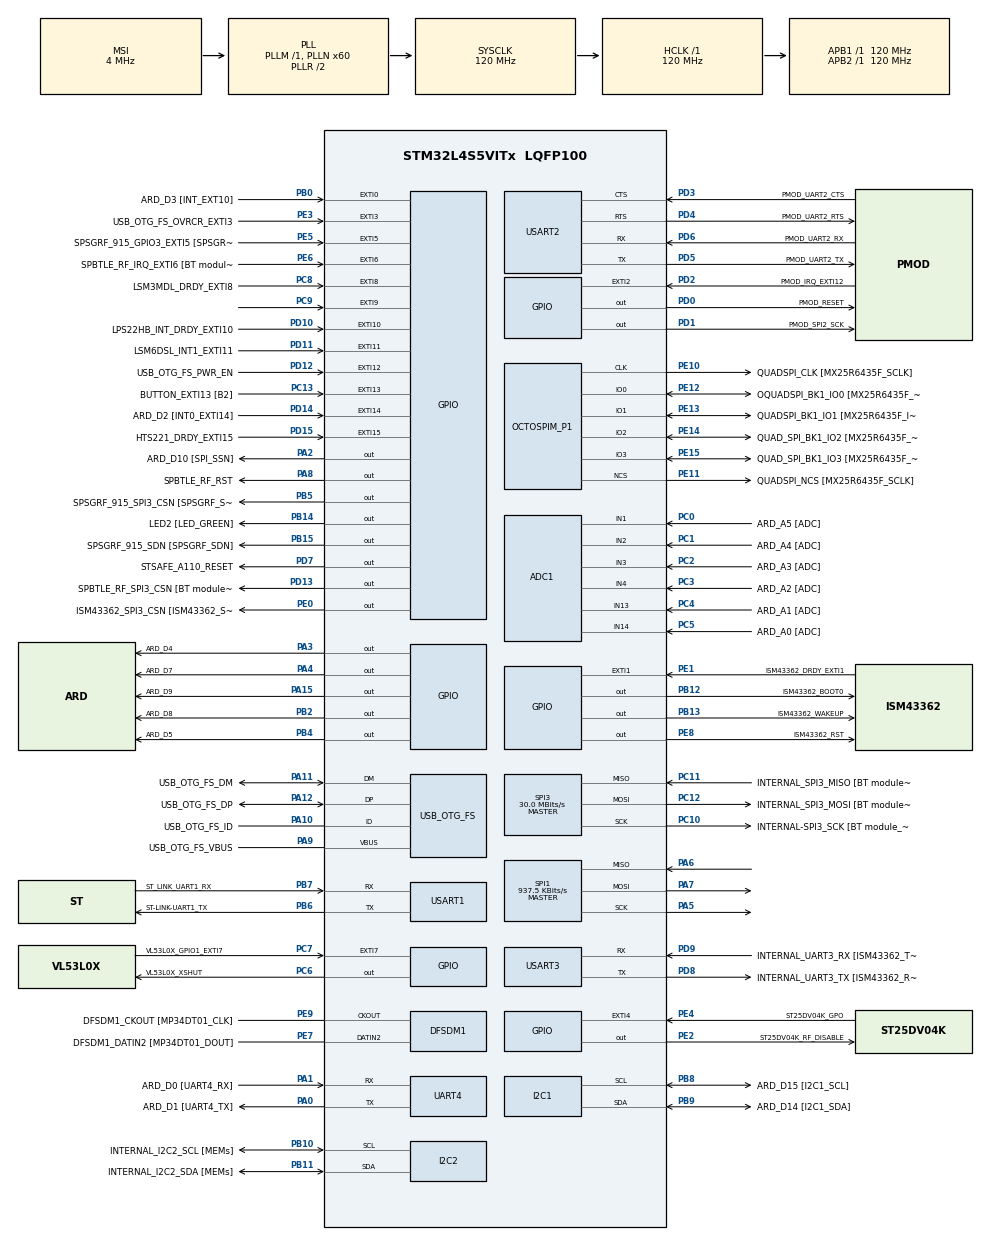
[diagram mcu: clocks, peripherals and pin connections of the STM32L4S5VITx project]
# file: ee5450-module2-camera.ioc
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PD12.GPIO_Label=USB_OTG_FS_PWR_EN
PC10.GPIO_PuPd=GPIO_NOPULL
PE10.GPIO_PuPd=GPIO_NOPULL
PD10.GPIO_PuPd=GPIO_NOPULL
PA15\ (JTDI).Signal=GPIO_Output
PC15-OSC32_OUT\ (PC15).Mode=LSE-External-Oscillator
PC14-OSC32_IN\ (PC14).Mode=LSE-External-Oscillator
PD8.GPIO_ModeDefaultPP=GPIO_MODE_AF_PP
PE13.GPIO_Mode=GPIO_MODE_AF_PP
NVIC.EXTI1_IRQn=true\:2\:0\:true\:false\:true\:true\:true
PD7.GPIO_PuPd=GPIO_NOPULL
SPI1.Direction=SPI_DIRECTION_2LINES
RCC.APB2TimFreq_Value=120000000
PC4.GPIO_Mode=GPIO_MODE_ANALOG_ADC_CONTROL
PB6.Signal=USART1_TX
PC7.Signal=GPXTI7
PB12.PinState=GPIO_PIN_RESET
SPI1.CalculateBaudRate=937.5 KBits/s
PD0.Signal=GPIO_Output
PD8.Signal=USART3_TX
PE1.Signal=GPXTI1
NVIC.EXTI15_10_IRQn=true\:2\:0\:true\:false\:true\:true\:true
PB7.GPIO_ModeDefaultPP=GPIO_MODE_AF_PP
PB12.GPIO_ModeDefaultOutputPP=GPIO_MODE_OUTPUT_PP
PC1.GPIO_PuPd=GPIO_NOPULL
PD1.GPIO_Label=PMOD_SPI2_SCK
PB12.GPIO_Label=ISM43362_BOOT0
PA13\ (JTMS/SWDIO).GPIO_Label=SYS_JTMS_SWDIO
PC4.GPIO_Label=ARD_A1 [ADC]
PB1.GPIO_Speed=GPIO_SPEED_FREQ_LOW
PE9.Signal=S_CKOUTDFSDM1
PB1.GPIO_Label=ARD_D6
SPI1.DataSize=SPI_DATASIZE_8BIT
PE4.GPIO_Label=ST25DV04K_GPO
PD14.GPIO_PuPd=GPIO_NOPULL
PA8.Signal=GPIO_Output
PE13.Mode=OCTOSPI1_IOL_Port1L
PB2.GPIO_PuPd=GPIO_NOPULL
PD11.GPIO_ModeDefaultEXTI=GPIO_MODE_IT_RISING
PA0.Signal=UART4_TX
PE9.GPIO_Mode=GPIO_MODE_AF_PP
Mcu.Package=LQFP100
PB9.Signal=I2C1_SDA
PB1.Signal=S_TIM3_CH4
PB14.GPIO_PuPd=GPIO_NOPULL
PD0.GPIO_ModeDefaultOutputPP=GPIO_MODE_OUTPUT_PP
SPI3.Mode=SPI_MODE_MASTER
PD12.Signal=GPXTI12
PB6.GPIO_FM6=__NULL
PA10.Signal=USB_OTG_FS_ID
PE12.GPIO_Label=OQUADSPI_BK1_IO0 [MX25R6435F_IO0]
PC11.Mode=Full_Duplex_Master
PE8.GPIO_Speed=GPIO_SPEED_FREQ_LOW
RCC.APB1TimFreq_Value=120000000
PD5.GPIO_Speed=GPIO_SPEED_FREQ_VERY_HIGH
PD3.GPIO_PuPd=GPIO_NOPULL
PE6.GPIO_PuPd=GPIO_NOPULL
PA4.GPIO_Label=ARD_D7
PA8.GPIO_Speed=GPIO_SPEED_FREQ_LOW
PD15.Signal=GPXTI15
RCC.HSI48_VALUE=48000000
PC6.GPIO_ModeDefaultOutputPP=GPIO_MODE_OUTPUT_PP
PA5.Mode=Full_Duplex_Master
PE12.Mode=OCTOSPI1_IOL_Port1L
ADC1.OffsetNumber-0\#ChannelRegularConversion=ADC_OFFSET_NONE
PC13.Signal=GPXTI13
PB6.GPIO_PuPd=GPIO_NOPULL
PD3.Signal=USART2_CTS
PC2.Signal=ADCx_IN3
PD15.GPIO_ModeDefaultEXTI=GPIO_MODE_IT_RISING
PD9.GPIO_ModeDefaultPP=GPIO_MODE_AF_PP
PD6.Mode=Asynchronous
PD10.Signal=GPXTI10
PC10.GPIO_Mode=GPIO_MODE_AF_PP
PB8.GPIO_Label=ARD_D15 [I2C1_SCL]
PE15.GPIO_Speed_High_Default=GPIO_SPEED_FREQ_VERY_HIGH
PB10.GPIO_Mode=GPIO_MODE_AF_OD
PA8.GPIO_Label=SPBTLE_RF_RST
PE8.GPIO_Label=ISM43362_RST
PB13.GPIO_Speed=GPIO_SPEED_FREQ_LOW
PD8.Mode=Asynchronous
PB14.Signal=GPIO_Output
PE2.GPIO_PuPd=GPIO_NOPULL
PA5.Signal=SPI1_SCK
PD7.PinState=GPIO_PIN_RESET
PC12.Mode=Full_Duplex_Master
PE1.GPIO_Label=ISM43362_DRDY_EXTI1
PB13.GPIO_PuPd=GPIO_NOPULL
PE14.Signal=OCTOSPIM_P1_IO2
PB15.GPIO_Label=SPSGRF_915_SDN [SPSGRF_SDN]
SPI1.Mode=SPI_MODE_MASTER
PD4.GPIO_Speed=GPIO_SPEED_FREQ_VERY_HIGH
PA0.GPIO_ModeDefaultPP=GPIO_MODE_AF_PP
PA1.GPIO_Label=ARD_D0 [UART4_RX]
PE3.GPIO_PuPd=GPIO_NOPULL
PA15\ (JTDI).GPIO_PuPd=GPIO_NOPULL
SH.ADCx_IN4.0=ADC1_IN4,IN4-Single-Ended
SPI1.NSSPMode=SPI_NSS_PULSE_DISABLE
PC7.GPIO_Label=VL53L0X_GPIO1_EXTI7
PC8.GPIO_PuPd=GPIO_NOPULL
ADC1.master=1
PE5.GPIO_Label=SPSGRF_915_GPIO3_EXTI5 [SPSGRF_GPIO_3]
PC12.GPIO_Label=INTERNAL_SPI3_MOSI [BT module_SPI_MOSI] [ISM43362_MOSI]
ProjectManager.HeapSize=0x200
PD0.GPIO_PuPd=GPIO_NOPULL
PD8.GPIO_Speed=GPIO_SPEED_FREQ_VERY_HIGH
NVIC.PriorityGroup=NVIC_PRIORITYGROUP_4
PE3.Signal=GPXTI3
PD2.Signal=GPXTI2
PB4\ (NJTRST).GPIO_PuPd=GPIO_NOPULL
Mcu.Family=STM32L4
PA6.Mode=Full_Duplex_Master
PH0-OSC_IN\ (PH0).Signal=RCC_OSC_IN
PE11.GPIO_Label=QUADSPI_NCS [MX25R6435F_SCLK]
PB2.GPIO_Speed=GPIO_SPEED_FREQ_LOW
PA0.GPIO_Label=ARD_D1 [UART4_TX]
PE2.GPIO_Speed=GPIO_SPEED_FREQ_LOW
PD9.GPIO_Speed=GPIO_SPEED_FREQ_VERY_HIGH
PD0.GPIO_Label=PMOD_RESET
PA11.Mode=OTG/Dual_Role_Device
PB4\ (NJTRST).GPIO_Speed=GPIO_SPEED_FREQ_LOW
PB13.GPIO_Label=ISM43362_WAKEUP
PD8.GPIO_PuPd=GPIO_NOPULL
PB15.Signal=GPIO_Output
PD9.Mode=Asynchronous
PD13.Signal=GPIO_Output
PC11.GPIO_PuPd=GPIO_NOPULL
PE11.GPIO_PuPd=GPIO_NOPULL
PA1.GPIO_ModeDefaultPP=GPIO_MODE_AF_PP
SH.ADCx_IN3.0=ADC1_IN3,IN3-Single-Ended
PD4.GPIO_Mode=GPIO_MODE_AF_PP
PD5.Mode=Asynchronous
PA9.GPIO_Mode=GPIO_MODE_INPUT
ADC1.Channel-0\#ChannelRegularConversion=ADC_CHANNEL_1
PH1-OSC_OUT\ (PH1).Mode=HSE-External-Oscillator
RCC.HSE_VALUE=8000000
PE2.GPIO_ModeDefaultOutputPP=GPIO_MODE_OUTPUT_PP
PE13.GPIO_PuPd=GPIO_NOPULL
PB0.GPIO_ModeDefaultEXTI=GPIO_MODE_IT_RISING
PD0.PinState=GPIO_PIN_RESET
PC11.GPIO_Label=INTERNAL_SPI3_MISO [BT module_SPI_MOSI] [ISM43362_MOSI]
PC13.GPIO_PuPd=GPIO_NOPULL
PB7.Signal=USART1_RX
PB7.GPIO_Label=ST_LINK_UART1_RX
PD13.GPIO_Label=SPBTLE_RF_SPI3_CSN [BT module_SPI_CS]
PA6.Signal=SPI1_MISO
PA15\ (JTDI).GPIO_ModeDefaultOutputPP=GPIO_MODE_OUTPUT_PP
PD5.GPIO_Label=PMOD_UART2_TX
SH.ADCx_IN1.0=ADC1_IN1,IN1-Single-Ended
PB5.GPIO_Label=SPSGRF_915_SPI3_CSN [SPSGRF_SPI_CS]
PE8.GPIO_ModeDefaultOutputPP=GPIO_MODE_OUTPUT_PP
PC5.Signal=ADCx_IN14
PD3.GPIO_Label=PMOD_UART2_CTS
PE14.GPIO_Mode=GPIO_MODE_AF_PP
PE7.Signal=S_DATAIN2DFSDM1
PD6.Signal=USART2_RX
PE2.GPIO_Label=ST25DV04K_RF_DISABLE
PB9.GPIO_FM9=__NULL
PA3.Signal=GPIO_Output
PE0.GPIO_PuPd=GPIO_NOPULL
PE3.GPIO_ModeDefaultEXTI=GPIO_MODE_IT_RISING
PB3\ (JTDO/TRACESWO).GPIO_Label=SYS_JTD0_SWO
RCC.MSI_VALUE=4000000
SH.ADCx_IN13.0=ADC1_IN13,IN13-Single-Ended
PE0.GPIO_ModeDefaultOutputPP=GPIO_MODE_OUTPUT_PP
PD15.GPIO_Label=HTS221_DRDY_EXTI15
PA10.Mode=OTG/Dual_Role_Device
PC11.Signal=SPI3_MISO
PC8.Signal=GPXTI8
PB4\ (NJTRST).PinState=GPIO_PIN_RESET
PC10.Mode=Full_Duplex_Master
PE4.GPIO_ModeDefaultEXTI=GPIO_MODE_IT_RISING
PE14.GPIO_Label=QUAD_SPI_BK1_IO2 [MX25R6435F_IO2]
PD9.Signal=USART3_RX
PA9.GPIO_PuPd=GPIO_NOPULL
PA12.GPIO_Label=USB_OTG_FS_DP
PH1-OSC_OUT\ (PH1).Signal=RCC_OSC_OUT
PD8.GPIO_Label=INTERNAL_UART3_TX [ISM43362_RX]
USART1.VirtualMode-Asynchronous=VM_ASYNC
PD4.GPIO_PuPd=GPIO_NOPULL
PA9.Mode=Activate_VBUS
PE0.PinState=GPIO_PIN_RESET
PB14.PinState=GPIO_PIN_RESET
PB10.GPIO_Label=INTERNAL_I2C2_SCL [MEMs]
PB9.Mode=I2C
RCC.USBFreq_Value=48000000
PD10.GPIO_Label=LPS22HB_INT_DRDY_EXTI10
PB14.GPIO_ModeDefaultOutputPP=GPIO_MODE_OUTPUT_PP
PA1.Signal=UART4_RX
PB6.GPIO_ModeDefaultPP=GPIO_MODE_AF_PP
PE10.GPIO_Speed_High_Default=GPIO_SPEED_FREQ_VERY_HIGH
PE10.GPIO_Mode=GPIO_MODE_AF_PP
board=B-L4S5I-IOT01A
PD13.GPIO_Speed=GPIO_SPEED_FREQ_LOW
RCC.VCOOutputFreq_Value=240000000
PA1.GPIO_Speed=GPIO_SPEED_FREQ_VERY_HIGH
RCC.ADCFreq_Value=48000000
PC1.GPIO_Label=ARD_A4 [ADC]
PE11.GPIO_Mode=GPIO_MODE_AF_PP
PD5.GPIO_PuPd=GPIO_NOPULL
PE14.GPIO_PuPd=GPIO_NOPULL
PA15\ (JTDI).GPIO_Label=ARD_D9
PE0.Signal=GPIO_Output
PE7.GPIO_Label=DFSDM1_DATIN2 [MP34DT01_DOUT]
PE12.Signal=OCTOSPIM_P1_IO0
PE12.GPIO_Mode=GPIO_MODE_AF_PP
RCC.SYSCLKFreq_VALUE=120000000
PC14-OSC32_IN\ (PC14).Signal=RCC_OSC32_IN
NVIC.EXTI9_5_IRQn=true\:2\:0\:true\:false\:true\:true\:true
PB2.GPIO_Label=ARD_D8
PE15.GPIO_PuPd=GPIO_NOPULL
PD3.GPIO_Mode=GPIO_MODE_AF_PP
RCC.HSI_VALUE=16000000
PA8.GPIO_PuPd=GPIO_NOPULL
PD14.GPIO_ModeDefaultEXTI=GPIO_MODE_IT_RISING
RCC.PLLN=60
PB8.GPIO_Speed=GPIO_SPEED_FREQ_VERY_HIGH
PC12.GPIO_Speed=GPIO_SPEED_FREQ_VERY_HIGH
PD6.GPIO_Speed=GPIO_SPEED_FREQ_VERY_HIGH
PD7.GPIO_ModeDefaultOutputPP=GPIO_MODE_OUTPUT_PP
PB12.Signal=GPIO_Output
PB0.GPIO_PuPd=GPIO_NOPULL
PA3.GPIO_Label=ARD_D4
PD6.GPIO_PuPd=GPIO_NOPULL
PB4\ (NJTRST).Signal=GPIO_Output
PD5.GPIO_ModeDefaultPP=GPIO_MODE_AF_PP
PE15.GPIO_Mode=GPIO_MODE_AF_PP
SPI3.Direction=SPI_DIRECTION_2LINES
SPI3.VirtualType=VM_MASTER
SPI1.VirtualType=VM_MASTER
PB10.Mode=I2C
PC12.Signal=SPI3_MOSI
PB14.GPIO_Label=LED2 [LED_GREEN]
PE8.GPIO_PuPd=GPIO_NOPULL
PB7.GPIO_FM7=__NULL
PC6.GPIO_Label=VL53L0X_XSHUT
PB6.GPIO_Label=ST-LINK-UART1_TX
PB13.Signal=GPIO_Output
PD3.GPIO_Speed=GPIO_SPEED_FREQ_VERY_HIGH
PD6.GPIO_Label=PMOD_UART2_RX
PE6.GPIO_Label=SPBTLE_RF_IRQ_EXTI6 [BT module_SPI_IRQ]
RCC.SYSCLKSource=RCC_SYSCLKSOURCE_PLLCLK
PB11.GPIO_Speed=GPIO_SPEED_FREQ_VERY_HIGH
USART3.VirtualMode-Asynchronous=VM_ASYNC
PA14\ (JTCK/SWCLK).Signal=SYS_JTCK-SWCLK
PD4.Signal=USART2_RTS
PB6.Mode=Asynchronous
PC3.Signal=ADCx_IN4
PE5.Signal=GPXTI5
PD10.GPIO_ModeDefaultEXTI=GPIO_MODE_IT_RISING
PA1.GPIO_PuPd=GPIO_NOPULL
PD2.GPIO_ModeDefaultEXTI=GPIO_MODE_IT_RISING
PB2.Signal=GPIO_Output
VP_OCTOSPI1_VS_quad.Mode=quad_mode
PE11.GPIO_Speed_High_Default=GPIO_SPEED_FREQ_VERY_HIGH
PA0.Mode=Asynchronous
PC11.GPIO_Speed=GPIO_SPEED_FREQ_VERY_HIGH
PE2.Signal=GPIO_Output
PA14\ (JTCK/SWCLK).Mode=Serial_Wire
PA8.GPIO_ModeDefaultOutputPP=GPIO_MODE_OUTPUT_PP
PD3.Mode=CTS_RTS
PE10.Signal=OCTOSPIM_P1_CLK
ADC1.SamplingTime-0\#ChannelRegularConversion=ADC_SAMPLETIME_2CYCLES_5
PA2.GPIO_ModeDefaultOutputPP=GPIO_MODE_OUTPUT_PP
SH.ADCx_IN14.0=ADC1_IN14,IN14-Single-Ended
PC6.GPIO_PuPd=GPIO_NOPULL
PB8.GPIO_PuPdOD=GPIO_PULLUP
PA14\ (JTCK/SWCLK).GPIO_Label=SYS_JTCK_SWCLK
PC2.GPIO_Mode=GPIO_MODE_ANALOG_ADC_CONTROL
PD4.Mode=CTS_RTS
PC12.GPIO_PuPd=GPIO_NOPULL
PB11.GPIO_Mode=GPIO_MODE_AF_OD
PE10.GPIO_Label=QUADSPI_CLK [MX25R6435F_SCLK]
PD9.GPIO_PuPd=GPIO_NOPULL
PB2.GPIO_ModeDefaultOutputPP=GPIO_MODE_OUTPUT_PP
PH0-OSC_IN\ (PH0).Mode=HSE-External-Oscillator
PC6.GPIO_Speed=GPIO_SPEED_FREQ_LOW
PE12.GPIO_PuPd=GPIO_NOPULL
PB7.GPIO_PuPd=GPIO_NOPULL
ADC1.Rank-0\#ChannelRegularConversion=1
PD9.GPIO_Label=INTERNAL_UART3_RX [ISM43362_TX]
PD2.GPIO_PuPd=GPIO_NOPULL
PA9.GPIO_Label=USB_OTG_FS_VBUS
PB10.GPIO_PuPdOD=GPIO_PULLUP
PB11.GPIO_PuPdOD=GPIO_PULLUP
PE10.Mode=O1_P1_CLK
PC6.Signal=GPIO_Output
PB11.GPIO_Label=INTERNAL_I2C2_SDA [MEMs]
PD7.Signal=GPIO_Output
PD1.Signal=GPIO_Output
PA11.GPIO_Label=USB_OTG_FS_DM
PE1.GPIO_PuPd=GPIO_NOPULL
PC0.Signal=ADCx_IN1
PD0.GPIO_Speed=GPIO_SPEED_FREQ_LOW
PA0.GPIO_Speed=GPIO_SPEED_FREQ_VERY_HIGH
PE0.GPIO_Speed=GPIO_SPEED_FREQ_LOW
PB11.Mode=I2C
PB14.GPIO_Speed=GPIO_SPEED_FREQ_LOW
PA9.Signal=USB_OTG_FS_VBUS
I2C1.Timing=0x307075B1
PC7.GPIO_PuPd=GPIO_NOPULL
PE9.GPIO_Label=DFSDM1_CKOUT [MP34DT01_CLK]
PB10.Signal=I2C2_SCL
PC6.PinState=GPIO_PIN_RESET
PE6.GPIO_ModeDefaultEXTI=GPIO_MODE_IT_RISING
PA15\ (JTDI).GPIO_Speed=GPIO_SPEED_FREQ_LOW
PD12.GPIO_ModeDefaultEXTI=GPIO_MODE_IT_RISING
PE7.GPIO_Speed=GPIO_SPEED_FREQ_LOW
PA1.Mode=Asynchronous
PB13.PinState=GPIO_PIN_RESET
PE15.Signal=OCTOSPIM_P1_IO3
PE8.Signal=GPIO_Output
PC11.GPIO_Mode=GPIO_MODE_AF_PP
PE4.GPIO_PuPd=GPIO_NOPULL
PA4.Signal=GPIO_Output
OCTOSPI1.MemoryType=HAL_OSPI_MEMTYPE_MACRONIX
PC12.GPIO_Mode=GPIO_MODE_AF_PP
PB5.Signal=GPIO_Output
PE13.GPIO_Label=QUADSPI_BK1_IO1 [MX25R6435F_IO1]
PD11.Signal=GPXTI11
PA11.Signal=USB_OTG_FS_DM
PC5.GPIO_Mode=GPIO_MODE_ANALOG_ADC_CONTROL
PE12.GPIO_Speed_High_Default=GPIO_SPEED_FREQ_VERY_HIGH
PC8.GPIO_ModeDefaultEXTI=GPIO_MODE_IT_RISING
PB8.Mode=I2C
PC3.GPIO_Label=ARD_A2 [ADC]
PA15\ (JTDI).PinState=GPIO_PIN_RESET
PB4\ (NJTRST).GPIO_Label=ARD_D5
PB6.GPIO_Speed=GPIO_SPEED_FREQ_VERY_HIGH
PB12.GPIO_PuPd=GPIO_NOPULL
PB0.Signal=GPXTI0
PC1.Signal=ADCx_IN2
PD2.GPIO_Label=PMOD_IRQ_EXTI12
PA13\ (JTMS/SWDIO).Signal=SYS_JTMS-SWDIO
PE15.Mode=OCTOSPI1_IOL_Port1L
PC3.GPIO_Mode=GPIO_MODE_ANALOG_ADC_CONTROL
PA2.GPIO_PuPd=GPIO_NOPULL
PE7.GPIO_PuPd=GPIO_NOPULL
PE8.PinState=GPIO_PIN_RESET
RCC.CortexFreq_Value=120000000
PB10.GPIO_Speed=GPIO_SPEED_FREQ_VERY_HIGH
SH.ADCx_IN2.0=ADC1_IN2,IN2-Single-Ended
PC10.Signal=SPI3_SCK
I2C2.Timing=0x307075B1
PA2.GPIO_Speed=GPIO_SPEED_FREQ_LOW
PC0.GPIO_Label=ARD_A5 [ADC]
PE9.GPIO_Speed=GPIO_SPEED_FREQ_LOW
PB0.GPIO_Label=ARD_D3 [INT_EXT10]
PC10.GPIO_Speed=GPIO_SPEED_FREQ_VERY_HIGH
PE14.GPIO_Speed_High_Default=GPIO_SPEED_FREQ_VERY_HIGH
PC13.GPIO_Label=BUTTON_EXTI13 [B2]
PB11.Signal=I2C2_SDA
ProjectManager.StackSize=0x400
PD11.GPIO_PuPd=GPIO_NOPULL
PA12.Signal=USB_OTG_FS_DP
PE11.Mode=OCTOSPI1_Port1_NCS
PD11.GPIO_Label=LSM6DSL_INT1_EXTI11
RCC.HCLKFreq_Value=120000000
PB13.GPIO_ModeDefaultOutputPP=GPIO_MODE_OUTPUT_PP
RCC.AHBFreq_Value=120000000
PC1.GPIO_Mode=GPIO_MODE_ANALOG_ADC_CONTROL
USART2.VirtualMode-Asynchronous=VM_ASYNC
PD7.GPIO_Speed=GPIO_SPEED_FREQ_LOW
PA2.PinState=GPIO_PIN_SET
PE13.Signal=OCTOSPIM_P1_IO1
PA10.GPIO_Label=USB_OTG_FS_ID
PE4.Signal=GPXTI4
PD7.GPIO_Label=STSAFE_A110_RESET
PC7.GPIO_ModeDefaultEXTI=GPIO_MODE_IT_RISING
PA0.GPIO_PuPd=GPIO_NOPULL
PA2.GPIO_Label=ARD_D10 [SPI_SSN]
PD15.GPIO_PuPd=GPIO_NOPULL
PE0.GPIO_Label=ISM43362_SPI3_CSN [ISM43362_SSN]
PB4\ (NJTRST).GPIO_ModeDefaultOutputPP=GPIO_MODE_OUTPUT_PP
PB9.GPIO_Speed=GPIO_SPEED_FREQ_VERY_HIGH
PE13.GPIO_Speed_High_Default=GPIO_SPEED_FREQ_VERY_HIGH
PC0.GPIO_PuPd=GPIO_NOPULL
SPI1.BaudRatePrescaler=SPI_BAUDRATEPRESCALER_128
PC2.GPIO_Label=ARD_A3 [ADC]
PA8.PinState=GPIO_PIN_RESET
RCC.PLLSAI1N=24
PB7.GPIO_Speed=GPIO_SPEED_FREQ_VERY_HIGH
PA7.Mode=Full_Duplex_Master
PA13\ (JTMS/SWDIO).Mode=Serial_Wire
PB9.GPIO_Label=ARD_D14 [I2C1_SDA]
PC10.GPIO_Label=INTERNAL-SPI3_SCK [BT module_SPI_MOSI] [ISM43362_MOSI]
PE2.PinState=GPIO_PIN_RESET
PC4.GPIO_PuPd=GPIO_NOPULL
PB8.GPIO_FM8=__NULL
PC4.Signal=ADCx_IN13
SH.S_DATAIN2DFSDM1.0=DFSDM1_DATIN2,PDM_SPI_input_from_ch2_and_internal_clock
PC15-OSC32_OUT\ (PC15).Signal=RCC_OSC32_OUT
PD5.Signal=USART2_TX
PE1.GPIO_ModeDefaultEXTI=GPIO_MODE_IT_RISING
VP_RNG_VS_RNG.Mode=RNG_Activate
PC5.GPIO_PuPd=GPIO_NOPULL
PD6.GPIO_ModeDefaultPP=GPIO_MODE_AF_PP
PC8.GPIO_Label=LSM3MDL_DRDY_EXTI8
PE15.GPIO_Label=QUAD_SPI_BK1_IO3 [MX25R6435F_IO3]
PB3\ (JTDO/TRACESWO).Signal=SYS_JTDO-SWO
ProjectManager.TargetToolchain=STM32CubeIDE
PE11.Signal=OCTOSPIM_P1_NCS
PB12.GPIO_Speed=GPIO_SPEED_FREQ_LOW
PE7.GPIO_Mode=GPIO_MODE_AF_PP
PB9.GPIO_Mode=GPIO_MODE_AF_OD
RCC.APB2Freq_Value=120000000
SPI3.CalculateBaudRate=30.0 MBits/s
PC0.GPIO_Mode=GPIO_MODE_ANALOG_ADC_CONTROL
PD4.GPIO_Label=PMOD_UART2_RTS
PE14.Mode=OCTOSPI1_IOL_Port1L
SH.S_CKOUTDFSDM1.0=DFSDM1_CKOUT,PDM_SPI_input_from_ch2_and_internal_clock
SPI3.BaudRatePrescaler=SPI_BAUDRATEPRESCALER_4
PD13.GPIO_PuPd=GPIO_NOPULL
PD14.GPIO_Label=ARD_D2 [INT0_EXTI14]
PC2.GPIO_PuPd=GPIO_NOPULL
PE6.Signal=GPXTI6
PB2.PinState=GPIO_PIN_RESET
Mcu.Name=STM32L4S5VITx
PA2.Signal=GPIO_Output
PD14.Signal=GPXTI14
PA12.Mode=OTG/Dual_Role_Device
PC13.GPIO_ModeDefaultEXTI=GPIO_MODE_IT_RISING_FALLING
PC5.GPIO_Label=ARD_A0 [ADC]
PD13.GPIO_ModeDefaultOutputPP=GPIO_MODE_OUTPUT_PP
PB7.Mode=Asynchronous
PB9.GPIO_PuPdOD=GPIO_PULLUP
ADC1.NbrOfConversionFlag=1
PB8.Signal=I2C1_SCL
PE3.GPIO_Label=USB_OTG_FS_OVRCR_EXTI3
PC9.Signal=GPXTI9
PD13.PinState=GPIO_PIN_RESET
PB8.GPIO_Mode=GPIO_MODE_AF_OD
RCC.APB1Freq_Value=120000000
PD12.GPIO_PuPd=GPIO_NOPULL
PC3.GPIO_PuPd=GPIO_NOPULL
SH.S_TIM3_CH4.0=TIM3_CH4
PA7.Signal=SPI1_MOSI
PE9.GPIO_PuPd=GPIO_NOPULL

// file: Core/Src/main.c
/* USER CODE BEGIN Header */
/**
  ******************************************************************************
  * @file           : main.c
  * @brief          : Main program body (only the threads are in this file)
  ******************************************************************************
  */
/* USER CODE END Header */
#include "main.h"
#include "adc.h"
#include "dfsdm.h"
#include "i2c.h"
#include "octospi.h"
#include "rng.h"
#include "spi.h"
#include "usart.h"
#include "usb_otg.h"
#include "gpio.h"

/* USER CODE BEGIN Includes */
#include <stdio.h>
#include "sensor_telemetry_setup.h"
#include "sensor_telemetry.h"
/* USER CODE END Includes */

/* USER CODE BEGIN PM */
/* USER CODE BEGIN PTD */
/* USER CODE END PM */

/* USER CODE BEGIN PV */
TX_EVENT_FLAGS_GROUP global_event_flags;
TX_BYTE_POOL global_byte_pool;
ULONG global_memory_area[(sizeof(struct global_data_t) / sizeof(ULONG)) + 10 * sizeof(ULONG)];
extern SPI_HandleTypeDef hspi_wifi;
/* USER CODE END PV */

void SystemClock_Config(void);
/* USER CODE BEGIN PFP */
void thread_camera_setup(ULONG global_data_ulong);
void thread_camera_stream(ULONG global_data_ulong);
void thread_network_setup(ULONG global_data_ulong);
_Noreturn void blink_PA_5(ULONG global_data_ulong);
_Noreturn void blink_PB_14(ULONG global_data_ulong);
_Noreturn void thread_temperature(ULONG global_data_ulong);
_Noreturn void thread_accelerometer(ULONG global_data_ulong);
/* USER CODE END PFP */

/* USER CODE BEGIN 0 */
/**
 * @brief interrupt handler to set software interrupts
 * @param GPIO_Pin
 */
void HAL_GPIO_EXTI_Callback(uint16_t GPIO_Pin) {
    if (GPIO_Pin == GPIO_PIN_13) {
        tx_event_flags_set(&global_event_flags, EVT_BUTTON_PRESSED, TX_OR);
    }
    else if (GPIO_Pin == GPIO_PIN_1) {
        SPI_WIFI_ISR();
    }
}

/**
 * @brief handle the spi3 interrupt (for Wifi/BLE)
 */
void SPI3_IRQHandler(void)
{
    HAL_SPI_IRQHandler(&hspi_wifi);
}

/**
 * @brief function for defining the ThreadX application
 * @param first_unused_memory
 */
void tx_application_define(void* first_unused_memory) {
    char* pointer = TX_NULL;
    volatile UINT status;

    systick_interval_set(TX_TIMER_TICKS_PER_SECOND);

    status = tx_event_flags_create(&global_event_flags, "global event flags");

    /* allocate global data structure */
    status = tx_byte_pool_create(&global_byte_pool, "global byte pool",
                                 global_memory_area, sizeof(struct global_data_t) + 10 * sizeof(ULONG));
    status = tx_byte_allocate(&global_byte_pool, (VOID**)&pointer,
                              sizeof(struct global_data_t), TX_NO_WAIT);
    struct global_data_t* global_data = (struct global_data_t*)pointer;
    global_data->interval_mqtt = 1;
    global_data->interval_accelerometer = 1;
    global_data->interval_temperature = 1;
    global_data->interval_ld1 = 1;
    global_data->interval_ld2 = 2;

    /* initialize synchronization primitives */
    status = tx_mutex_create(&global_data->mutex_mqtt, "MQTT client mutex", TX_NO_INHERIT);
    status = tx_mutex_create(&global_data->mutex_i2c2, "I2C channel 2 mutex", TX_NO_INHERIT);
    status = tx_mutex_create(&global_data->mutex_network_reset, "network setup mutex", TX_NO_INHERIT);

    /* allocate thread-local stacks */
    status = tx_byte_pool_create(&global_data->byte_pool_0, "byte pool 0",
                        global_data->memory_area, BYTE_POOL_SIZE);

    status = tx_byte_allocate(&global_data->byte_pool_0, (VOID **) &pointer, STACK_SIZE, TX_NO_WAIT);
    status = tx_thread_create(&global_data->thread_camera_setup, "thread camera setup",
                              thread_camera_setup, (ULONG)global_data,
                              pointer, STACK_SIZE,
                              1, 1, TX_NO_TIME_SLICE, TX_AUTO_START);
    if (status != TX_SUCCESS)
        printf("thread creation failed\r\n");

    status = tx_byte_allocate(&global_data->byte_pool_0, (VOID **) &pointer, STACK_SIZE, TX_NO_WAIT);
    status = tx_thread_create(&global_data->threads[2], "thread camera stream",
                              thread_camera_stream, (ULONG)global_data,
                              pointer, STACK_SIZE,
                              2, 2, TX_NO_TIME_SLICE, TX_AUTO_START);
    if (status != TX_SUCCESS)
        printf("thread creation failed\r\n");

    status = tx_byte_allocate(&global_data->byte_pool_0, (VOID **) &pointer, STACK_SIZE, TX_NO_WAIT);
    status = tx_thread_create(&global_data->thread_network_setup, "thread net test",
                              thread_network_setup, (ULONG)global_data,
                              pointer, STACK_SIZE,
                              1, 1, TX_NO_TIME_SLICE, TX_AUTO_START);
    if (status != TX_SUCCESS)
        printf("thread creation failed\r\n");

//    tx_byte_allocate(&global_data->byte_pool_0, (VOID **) &pointer, STACK_SIZE, TX_NO_WAIT);
//    status = tx_thread_create(&global_data->threads[2], "thread 2",
//                              thread_temperature, (ULONG)global_data,
//                              pointer, STACK_SIZE,
//                              2, 2, TX_NO_TIME_SLICE, TX_AUTO_START);
//    if (status != TX_SUCCESS)
//        printf("thread creation failed\r\n");
//
//    tx_byte_allocate(&global_data->byte_pool_0, (VOID **) &pointer, STACK_SIZE, TX_NO_WAIT);
//    status = tx_thread_create(&global_data->threads[3], "thread 3",
//                              thread_accelerometer, (ULONG)global_data,
//                              pointer, STACK_SIZE,
//                              2, 2, TX_NO_TIME_SLICE, TX_AUTO_START);
//    if (status != TX_SUCCESS)
//        printf("thread creation failed\r\n");
}

void thread_camera_setup(ULONG global_data_ulong) {
    struct global_data_t* global_data = (struct global_data_t*)global_data_ulong;
    volatile UINT status;
    HAL_GPIO_WritePin(GPIOA, GPIO_PIN_2, GPIO_PIN_SET);
    OV2640_Init(&hi2c1);
    tx_thread_sleep(1);
    OV2640_ResolutionOptions(RES_640X480);
    tx_thread_sleep(1);
    arducam_init(&hspi1, GPIOA, GPIO_PIN_2);
    status = arducam_get_version();
    while (status != 0x73) {
        status = arducam_get_version();
    }

    tx_event_flags_set(&global_event_flags, EVT_CAMERA_READY, TX_OR);
}

/**
 * @brief setup the network by connecting to the Wifi network and using nxduo to test MQTT
 * @param global_data_ulong ->interval_mqtt: interval of sending out mqtt messages
 */
void thread_network_setup(ULONG global_data_ulong) {
    struct global_data_t* global_data = (struct global_data_t*)global_data_ulong;
    volatile UINT status;
    uint32_t tick_interval = 100 * global_data->interval_mqtt;
    ULONG current_tick;
    const size_t message_size = 30;
    char message[message_size + 1];
    const size_t topic_size = 30;
    char topic[topic_size + 1];
    memset(topic, 0, topic_size + 1);
    memset(message, 0, message_size + 1);

    status = setup_wifi(false);
    if (status != 0)
        return;
    status = setup_nx_wifi(global_data);
    if (status != 0)
        return;
    status = setup_nx_mqtt_and_connect(global_data);
    if (status != 0)
        return;

    snprintf(topic, topic_size, "board_test/hello");
    snprintf(message, message_size, "board says Hello!!!");
    status = send_nx_mqtt_message(global_data, topic, message, 0);
    if (status != 0)
        return;

    for (size_t i = 0; i < 7; i++) {
        current_tick = tx_time_get();
        snprintf(message, message_size, "hello the time is: %lu", current_tick);
        status = send_nx_mqtt_message(global_data, topic, message, 0);
        if (status != 0)
            return;
        tx_thread_sleep(tick_interval / 4);
    }

    tx_event_flags_set(&global_event_flags, EVT_WIFI_READY, TX_OR);
}

/**
 * @brief thread that blinks PB14 at given interval.
 * @param global_data_ulong ->interval_ld2: interval of blinking ld2 at 50% duty cycle
 */
_Noreturn void blink_PB_14(ULONG global_data_ulong) {
    struct global_data_t* global_data = (struct global_data_t*)global_data_ulong;
    uint32_t period_ticks = (global_data->interval_ld2 * 100) / 2;
    while(1) {
        HAL_GPIO_WritePin(GPIOB, GPIO_PIN_14, GPIO_PIN_SET);
        tx_thread_sleep(period_ticks);  // this is in ticks, which is default 100 per second.
        HAL_GPIO_WritePin(GPIOB, GPIO_PIN_14, GPIO_PIN_RESET);
        tx_thread_sleep(period_ticks);
    }
}

/**
 * @brief utility for resetting the network setup thread
 * @param global_data: pointer to the global data strcuture
 */
void reset_network_thread(struct global_data_t* global_data) {
    ULONG actual_flags;
    // the mutex check that another thread isn't resetting
    UINT status = tx_mutex_get(&global_data->mutex_network_reset, TX_NO_WAIT);
    if (status == TX_SUCCESS) {
        tx_event_flags_set(&global_event_flags, EVT_WIFI_READY, TX_AND_CLEAR);
        status = tx_thread_reset(&global_data->thread_network_setup);  // reset network setup thread
        printf("%d", status);
        status = tx_thread_resume(&global_data->thread_network_setup);  // start the network setup thread
    }
    tx_event_flags_get(&global_event_flags, EVT_WIFI_READY, TX_AND, &actual_flags, TX_WAIT_FOREVER);
    tx_mutex_put(&global_data->mutex_network_reset);  // if not owned, will error out anyway
}

/**
 * @brief thread that reads an image from the camera and sends it out via MQTT
 * @param global_data_ulong
 */
_Noreturn void thread_camera_stream(ULONG global_data_ulong) {
    ULONG actual_flags;
    struct global_data_t* global_data = (struct global_data_t*) global_data_ulong;
    const size_t CHUNK_SIZE = 4096;
    // header "img_id: 000, chunk_id: 000, num_chunks: 000, chunk_size: 000, data:" is 68 characters
    const size_t HEADER_SIZE = 68;
    const size_t MESSAGE_SIZE = HEADER_SIZE + CHUNK_SIZE;
    char message_buffer[MESSAGE_SIZE];
    const size_t topic_size = 30;
    char topic[topic_size + 1];
    memset(topic, 0, topic_size + 1);
    memset(message_buffer, 0, MESSAGE_SIZE);
    snprintf(topic, topic_size, "board_test/camera");
    uint8_t image_id = 0;

    tx_event_flags_get(&global_event_flags, EVT_WIFI_READY | EVT_CAMERA_READY, TX_AND, &actual_flags, TX_WAIT_FOREVER);

    while (1) {
        size_t num_bytes = arducam_read_image(FRAMEBUFFER_SIZE, global_data->framebuffer);
        size_t num_chunks = num_bytes / CHUNK_SIZE + (num_bytes % CHUNK_SIZE != 0);

        // trying to send out this one image in chunks!
        for (size_t chunk_id = 0; chunk_id < num_chunks; chunk_id++) {
            snprintf(message_buffer, HEADER_SIZE + 1,
                     "img_id: %3u, chunk_id: %3u, num_chunks: %3u, chunk_size: %3u, data:",
                     image_id, chunk_id, num_chunks, CHUNK_SIZE);
            memcpy(&(message_buffer[HEADER_SIZE]), &(global_data->framebuffer[chunk_id * CHUNK_SIZE]), CHUNK_SIZE);

            send_nx_mqtt_message(global_data, topic, message_buffer, MESSAGE_SIZE);
        }

        image_id++;
        tx_thread_sleep(200);
    }
}

/**
 * @brief thread that reads the temperature sensor value at given interval
 * @param global_data_ulong ->interval_temperature: interval in seconds to read the tsensor
 */
_Noreturn void thread_temperature(ULONG global_data_ulong) {
    UINT status;
    ULONG actual_flags;
    struct global_data_t* global_data = (struct global_data_t*)global_data_ulong;
    uint32_t period_ticks = global_data->interval_temperature * 100;

    const size_t message_size = 40;
    char message[message_size + 1];
    const size_t topic_size = 30;
    char topic[topic_size + 1];
    memset(topic, 0, topic_size + 1);
    memset(message, 0, message_size + 1);
    snprintf(topic, topic_size, "board_test/temperature");

    BSP_TSENSOR_Init();
    tx_event_flags_get(&global_event_flags, EVT_WIFI_READY, TX_AND, &actual_flags, TX_WAIT_FOREVER);

    while (1) {
        get_temperature_message(global_data, message, message_size);
        status = send_nx_mqtt_message(global_data, topic, message, 0);
        if (status != NX_SUCCESS) {
            reset_network_thread(global_data);
        }
        tx_thread_sleep(period_ticks);
    }
}

/**
 * @brief thread that reads the accelerometer XYZ at given interval
 * @param global_data_ulong ->interval_accelerometer: interval in seconds to read the accelerometer
 */
_Noreturn void thread_accelerometer(ULONG global_data_ulong) {
    UINT status;
    ULONG actual_flags;
    struct global_data_t* global_data = (struct global_data_t*)global_data_ulong;
    uint32_t period_ticks = (global_data->interval_accelerometer * 100);

    const size_t message_size = 40;
    char message[message_size + 1];
    const size_t topic_size = 30;
    char topic[topic_size + 1];
    memset(topic, 0, topic_size + 1);
    memset(message, 0, message_size + 1);
    snprintf(topic, topic_size, "board_test/accelerometer");

    ACCELERO_StatusTypeDef xl_status = BSP_ACCELERO_Init();
    if (xl_status != ACCELERO_OK)
        printf("ERROR!");
    tx_event_flags_get(&global_event_flags, EVT_WIFI_READY, TX_AND, &actual_flags, TX_WAIT_FOREVER);

    while (1) {
        get_accelerometer_message(global_data, message, message_size);
        status = send_nx_mqtt_message(global_data, topic, message, 0);
        if (status != NX_SUCCESS) {
            reset_network_thread(global_data);
        }
        tx_thread_sleep(period_ticks);
    }
}

/* USER CODE END 0 */

int main(void)
{

  /* MCU Configuration--------------------------------------------------------*/

  /* Reset of all peripherals, Initializes the Flash interface and the Systick. */
  HAL_Init();

  /* Configure the system clock */
  SystemClock_Config();

  /* Initialize all configured peripherals */
  MX_GPIO_Init();
  MX_ADC1_Init();
  MX_DFSDM1_Init();
  MX_I2C1_Init();
  MX_I2C2_Init();
  MX_OCTOSPI1_Init();
  MX_SPI3_Init();
  MX_UART4_Init();
  MX_USART1_UART_Init();
  MX_USART2_UART_Init();
  MX_USART3_UART_Init();
  MX_USB_OTG_FS_USB_Init();
  MX_RNG_Init();
  MX_SPI1_Init();
  /* USER CODE BEGIN 2 */
  tx_kernel_enter();
  /* USER CODE END 2 */

  /* Infinite loop */
  while (1)
  {

  }
}

void SystemClock_Config(void)
{
  RCC_OscInitTypeDef RCC_OscInitStruct = {0};
  RCC_ClkInitTypeDef RCC_ClkInitStruct = {0};
  RCC_PeriphCLKInitTypeDef PeriphClkInit = {0};

  /** Configure the main internal regulator output voltage
  */
  if (HAL_PWREx_ControlVoltageScaling(PWR_REGULATOR_VOLTAGE_SCALE1_BOOST) != HAL_OK)
  {
    Error_Handler();
  }
  /** Configure LSE Drive Capability
  */
  HAL_PWR_EnableBkUpAccess();
  __HAL_RCC_LSEDRIVE_CONFIG(RCC_LSEDRIVE_LOW);
  /** Initializes the RCC Oscillators according to the specified parameters
  * in the RCC_OscInitTypeDef structure.
  */
  RCC_OscInitStruct.OscillatorType = RCC_OSCILLATORTYPE_LSE|RCC_OSCILLATORTYPE_MSI;
  RCC_OscInitStruct.LSEState = RCC_LSE_ON;
  RCC_OscInitStruct.MSIState = RCC_MSI_ON;
  RCC_OscInitStruct.MSICalibrationValue = 0;
  RCC_OscInitStruct.MSIClockRange = RCC_MSIRANGE_6;
  RCC_OscInitStruct.PLL.PLLState = RCC_PLL_ON;
  RCC_OscInitStruct.PLL.PLLSource = RCC_PLLSOURCE_MSI;
  RCC_OscInitStruct.PLL.PLLM = 1;
  RCC_OscInitStruct.PLL.PLLN = 60;
  RCC_OscInitStruct.PLL.PLLP = RCC_PLLP_DIV2;
  RCC_OscInitStruct.PLL.PLLQ = RCC_PLLQ_DIV2;
  RCC_OscInitStruct.PLL.PLLR = RCC_PLLR_DIV2;
  if (HAL_RCC_OscConfig(&RCC_OscInitStruct) != HAL_OK)
  {
    Error_Handler();
  }
  /** Initializes the CPU, AHB and APB buses clocks
  */
  RCC_ClkInitStruct.ClockType = RCC_CLOCKTYPE_HCLK|RCC_CLOCKTYPE_SYSCLK
                              |RCC_CLOCKTYPE_PCLK1|RCC_CLOCKTYPE_PCLK2;
  RCC_ClkInitStruct.SYSCLKSource = RCC_SYSCLKSOURCE_PLLCLK;
  RCC_ClkInitStruct.AHBCLKDivider = RCC_SYSCLK_DIV1;
  RCC_ClkInitStruct.APB1CLKDivider = RCC_HCLK_DIV1;
  RCC_ClkInitStruct.APB2CLKDivider = RCC_HCLK_DIV1;

  if (HAL_RCC_ClockConfig(&RCC_ClkInitStruct, FLASH_LATENCY_5) != HAL_OK)
  {
    Error_Handler();
  }
  PeriphClkInit.PeriphClockSelection = RCC_PERIPHCLK_USART1|RCC_PERIPHCLK_USART2
                              |RCC_PERIPHCLK_USART3|RCC_PERIPHCLK_UART4
                              |RCC_PERIPHCLK_I2C1|RCC_PERIPHCLK_I2C2
                              |RCC_PERIPHCLK_DFSDM1|RCC_PERIPHCLK_USB
                              |RCC_PERIPHCLK_RNG|RCC_PERIPHCLK_ADC
                              |RCC_PERIPHCLK_OSPI;
  PeriphClkInit.Usart1ClockSelection = RCC_USART1CLKSOURCE_PCLK2;
  PeriphClkInit.Usart2ClockSelection = RCC_USART2CLKSOURCE_PCLK1;
  PeriphClkInit.Usart3ClockSelection = RCC_USART3CLKSOURCE_PCLK1;
  PeriphClkInit.Uart4ClockSelection = RCC_UART4CLKSOURCE_PCLK1;
  PeriphClkInit.I2c1ClockSelection = RCC_I2C1CLKSOURCE_PCLK1;
  PeriphClkInit.I2c2ClockSelection = RCC_I2C2CLKSOURCE_PCLK1;
  PeriphClkInit.AdcClockSelection = RCC_ADCCLKSOURCE_PLLSAI1;
  PeriphClkInit.Dfsdm1ClockSelection = RCC_DFSDM1CLKSOURCE_PCLK;
  PeriphClkInit.OspiClockSelection = RCC_OSPICLKSOURCE_SYSCLK;
  PeriphClkInit.UsbClockSelection = RCC_USBCLKSOURCE_PLLSAI1;
  PeriphClkInit.RngClockSelection = RCC_RNGCLKSOURCE_PLLSAI1;
  PeriphClkInit.PLLSAI1.PLLSAI1Source = RCC_PLLSOURCE_MSI;
  PeriphClkInit.PLLSAI1.PLLSAI1M = 1;
  PeriphClkInit.PLLSAI1.PLLSAI1N = 24;
  PeriphClkInit.PLLSAI1.PLLSAI1P = RCC_PLLP_DIV2;
  PeriphClkInit.PLLSAI1.PLLSAI1Q = RCC_PLLQ_DIV2;
  PeriphClkInit.PLLSAI1.PLLSAI1R = RCC_PLLR_DIV2;
  PeriphClkInit.PLLSAI1.PLLSAI1ClockOut = RCC_PLLSAI1_48M2CLK|RCC_PLLSAI1_ADC1CLK;
  if (HAL_RCCEx_PeriphCLKConfig(&PeriphClkInit) != HAL_OK)
  {
    Error_Handler();
  }
  /** Enable MSI Auto calibration
  */
  HAL_RCCEx_EnableMSIPLLMode();
}

void Error_Handler(void)
{
  __disable_irq();
  while (1)
  {
  }
}

/************************ (C) COPYRIGHT STMicroelectronics *****END OF FILE****/
